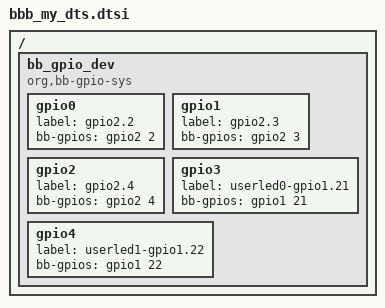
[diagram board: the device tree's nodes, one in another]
/{

bb_gpio_dev{
	compatible="org,bb-gpio-sys";
	gpio0{
		label="gpio2.2";
		bb-gpios=<&gpio2 2 GPIO_ACTIVE_HIGH>;  // <gpiocontroller pin active_state_slave>
	};
	gpio1{
		label="gpio2.3";
		bb-gpios=<&gpio2 3 GPIO_ACTIVE_HIGH>;

	};
	gpio2{

		label="gpio2.4";
		bb-gpios=<&gpio2 4 GPIO_ACTIVE_HIGH>;
	

	};
	
	gpio3{
		label="userled0-gpio1.21";
		bb-gpios=<&gpio1 21 GPIO_ACTIVE_HIGH>;
		
	};
	
	gpio4{
		label="userled1-gpio1.22";
		bb-gpios=<&gpio1 22 GPIO_ACTIVE_HIGH>;

	};



};




};
